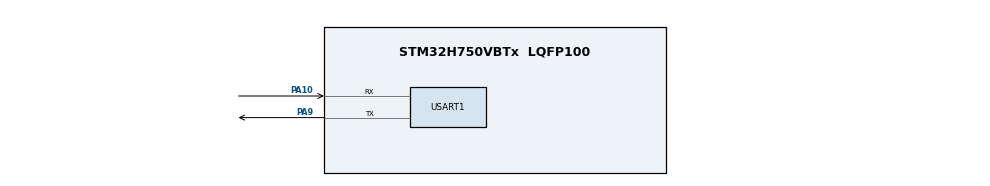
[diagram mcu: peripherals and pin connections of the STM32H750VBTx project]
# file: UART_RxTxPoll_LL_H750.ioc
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Mcu.Family=STM32H7
Mcu.Name=STM32H750VBTx
Mcu.Package=LQFP100
NVIC.PriorityGroup=NVIC_PRIORITYGROUP_4
PA10.Mode=Asynchronous
PA10.Signal=USART1_RX
PA13\ (JTMS/SWDIO).Mode=Serial_Wire
PA13\ (JTMS/SWDIO).Signal=DEBUG_JTMS-SWDIO
PA14\ (JTCK/SWCLK).Mode=Serial_Wire
PA14\ (JTCK/SWCLK).Signal=DEBUG_JTCK-SWCLK
PA9.Mode=Asynchronous
PA9.Signal=USART1_TX
PH0-OSC_IN\ (PH0).Mode=HSE-External-Oscillator
PH0-OSC_IN\ (PH0).Signal=RCC_OSC_IN
PH1-OSC_OUT\ (PH1).Mode=HSE-External-Oscillator
PH1-OSC_OUT\ (PH1).Signal=RCC_OSC_OUT
ProjectManager.HeapSize=0x200
ProjectManager.StackSize=0x400
ProjectManager.TargetToolchain=STM32CubeIDE
RCC.ADCFreq_Value=50390625
RCC.APB1Freq_Value=120000000
RCC.APB2Freq_Value=60000000
RCC.APB3Freq_Value=120000000
RCC.APB4Freq_Value=120000000
RCC.CortexFreq_Value=240000000
RCC.D2PPRE2=RCC_APB2_DIV2
RCC.DIVM1=25
RCC.DIVN1=480
RCC.HCLKFreq_Value=120000000
RCC.HPRE=RCC_HCLK_DIV2
RCC.PLLSourceVirtual=RCC_PLLSOURCE_HSE
RCC.SYSCLKFreq_VALUE=240000000
RCC.SYSCLKSource=RCC_SYSCLKSOURCE_PLLCLK
RCC.USBFreq_Value=240000000
USART1.VirtualMode-Asynchronous=VM_ASYNC
board=custom

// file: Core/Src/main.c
/* USER CODE BEGIN Header */
/**
  ******************************************************************************
  * @file           : main.c
  * @brief          : Main program body
  ******************************************************************************
  * @attention
  *
  * Copyright (c) 2023 STMicroelectronics.
  * All rights reserved.
  *
  * This software is licensed under terms that can be found in the LICENSE file
  * in the root directory of this software component.
  * If no LICENSE file comes with this software, it is provided AS-IS.
  *
  ******************************************************************************
  */
/* USER CODE END Header */
#include "main.h"

void SystemClock_Config(void);
static void MX_GPIO_Init(void);
static void MX_USART1_UART_Init(void);

int main(void)
{

  /* MCU Configuration--------------------------------------------------------*/

  /* Reset of all peripherals, Initializes the Flash interface and the Systick. */
  LL_APB4_GRP1_EnableClock(LL_APB4_GRP1_PERIPH_SYSCFG);

  /* System interrupt init*/
  NVIC_SetPriorityGrouping(NVIC_PRIORITYGROUP_4);

  /* SysTick_IRQn interrupt configuration */
  NVIC_SetPriority(SysTick_IRQn, NVIC_EncodePriority(NVIC_GetPriorityGrouping(),15, 0));

  /* Configure the system clock */
  SystemClock_Config();

  /* Initialize all configured peripherals */
  MX_GPIO_Init();
  MX_USART1_UART_Init();

  /* Infinite loop */
  /* USER CODE BEGIN WHILE */

  uint8_t data; // 用来暂存数据

  while (1)
  {
	  while(!LL_USART_IsActiveFlag_RXNE(USART1)); // 等待接收数据寄存器不为空

	  data = LL_USART_ReceiveData8(USART1); // 读取收到的数据

	  while(!LL_USART_IsActiveFlag_TXE(USART1)); // 等待发送数据数据寄存器为空

	  LL_USART_TransmitData8(USART1, data); // 发送数据

    /* USER CODE END WHILE */

  }
}

void SystemClock_Config(void)
{
  LL_FLASH_SetLatency(LL_FLASH_LATENCY_2);
  while(LL_FLASH_GetLatency()!= LL_FLASH_LATENCY_2)
  {
  }
  LL_PWR_ConfigSupply(LL_PWR_LDO_SUPPLY);
  LL_PWR_SetRegulVoltageScaling(LL_PWR_REGU_VOLTAGE_SCALE2);
  while (LL_PWR_IsActiveFlag_VOS() == 0)
  {
  }
  LL_RCC_HSE_Enable();

   /* Wait till HSE is ready */
  while(LL_RCC_HSE_IsReady() != 1)
  {

  }
  LL_RCC_PLL_SetSource(LL_RCC_PLLSOURCE_HSE);
  LL_RCC_PLL1P_Enable();
  LL_RCC_PLL1R_Enable();
  LL_RCC_PLL1_SetVCOInputRange(LL_RCC_PLLINPUTRANGE_1_2);
  LL_RCC_PLL1_SetVCOOutputRange(LL_RCC_PLLVCORANGE_WIDE);
  LL_RCC_PLL1_SetM(25);
  LL_RCC_PLL1_SetN(480);
  LL_RCC_PLL1_SetP(2);
  LL_RCC_PLL1_SetQ(2);
  LL_RCC_PLL1_SetR(2);
  LL_RCC_PLL1_Enable();

   /* Wait till PLL is ready */
  while(LL_RCC_PLL1_IsReady() != 1)
  {
  }

   /* Intermediate AHB prescaler 2 when target frequency clock is higher than 80 MHz */
   LL_RCC_SetAHBPrescaler(LL_RCC_AHB_DIV_2);

  LL_RCC_SetSysClkSource(LL_RCC_SYS_CLKSOURCE_PLL1);

   /* Wait till System clock is ready */
  while(LL_RCC_GetSysClkSource() != LL_RCC_SYS_CLKSOURCE_STATUS_PLL1)
  {

  }
  LL_RCC_SetSysPrescaler(LL_RCC_SYSCLK_DIV_1);
  LL_RCC_SetAHBPrescaler(LL_RCC_AHB_DIV_2);
  LL_RCC_SetAPB1Prescaler(LL_RCC_APB1_DIV_1);
  LL_RCC_SetAPB2Prescaler(LL_RCC_APB2_DIV_2);
  LL_RCC_SetAPB3Prescaler(LL_RCC_APB3_DIV_1);
  LL_RCC_SetAPB4Prescaler(LL_RCC_APB4_DIV_1);

  LL_Init1msTick(240000000);

  LL_SetSystemCoreClock(240000000);
}

static void MX_USART1_UART_Init(void)
{

  LL_USART_InitTypeDef USART_InitStruct = {0};

  LL_GPIO_InitTypeDef GPIO_InitStruct = {0};

  LL_RCC_SetUSARTClockSource(LL_RCC_USART16_CLKSOURCE_PCLK2);

  /* Peripheral clock enable */
  LL_APB2_GRP1_EnableClock(LL_APB2_GRP1_PERIPH_USART1);

  LL_AHB4_GRP1_EnableClock(LL_AHB4_GRP1_PERIPH_GPIOA);
  /**USART1 GPIO Configuration
  PA9   ------> USART1_TX
  PA10   ------> USART1_RX
  */
  GPIO_InitStruct.Pin = LL_GPIO_PIN_9|LL_GPIO_PIN_10;
  GPIO_InitStruct.Mode = LL_GPIO_MODE_ALTERNATE;
  GPIO_InitStruct.Speed = LL_GPIO_SPEED_FREQ_LOW;
  GPIO_InitStruct.OutputType = LL_GPIO_OUTPUT_PUSHPULL;
  GPIO_InitStruct.Pull = LL_GPIO_PULL_NO;
  GPIO_InitStruct.Alternate = LL_GPIO_AF_7;
  LL_GPIO_Init(GPIOA, &GPIO_InitStruct);

  USART_InitStruct.PrescalerValue = LL_USART_PRESCALER_DIV1;
  USART_InitStruct.BaudRate = 115200;
  USART_InitStruct.DataWidth = LL_USART_DATAWIDTH_8B;
  USART_InitStruct.StopBits = LL_USART_STOPBITS_1;
  USART_InitStruct.Parity = LL_USART_PARITY_NONE;
  USART_InitStruct.TransferDirection = LL_USART_DIRECTION_TX_RX;
  USART_InitStruct.HardwareFlowControl = LL_USART_HWCONTROL_NONE;
  USART_InitStruct.OverSampling = LL_USART_OVERSAMPLING_16;
  LL_USART_Init(USART1, &USART_InitStruct);
  LL_USART_SetTXFIFOThreshold(USART1, LL_USART_FIFOTHRESHOLD_1_8);
  LL_USART_SetRXFIFOThreshold(USART1, LL_USART_FIFOTHRESHOLD_1_8);
  LL_USART_DisableFIFO(USART1);
  LL_USART_ConfigAsyncMode(USART1);

  LL_USART_Enable(USART1);

  /* Polling USART1 initialisation */
  while((!(LL_USART_IsActiveFlag_TEACK(USART1))) || (!(LL_USART_IsActiveFlag_REACK(USART1))))
  {
  }

}

static void MX_GPIO_Init(void)
{

  /* GPIO Ports Clock Enable */
  LL_AHB4_GRP1_EnableClock(LL_AHB4_GRP1_PERIPH_GPIOH);
  LL_AHB4_GRP1_EnableClock(LL_AHB4_GRP1_PERIPH_GPIOA);

}

void Error_Handler(void)
{
  __disable_irq();
  while (1)
  {
  }
}
